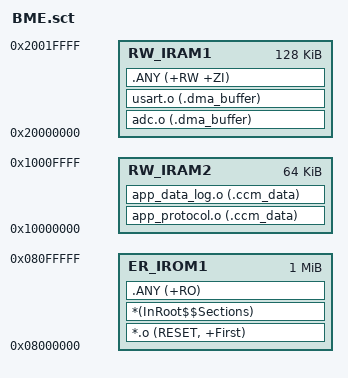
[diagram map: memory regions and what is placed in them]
LR_IROM1 0x08000000 0x00100000
{
  ER_IROM1 0x08000000 0x00100000
  {
    *.o (RESET, +First)
    *(InRoot$$Sections)
    .ANY (+RO)
  }

  RW_IRAM2 0x10000000 0x00010000
  {
    app_protocol.o (.ccm_data)
    app_data_log.o (.ccm_data)
  }

  RW_IRAM1 0x20000000 0x00020000
  {
    adc.o (.dma_buffer)
    usart.o (.dma_buffer)
    .ANY (+RW +ZI)
  }
}
